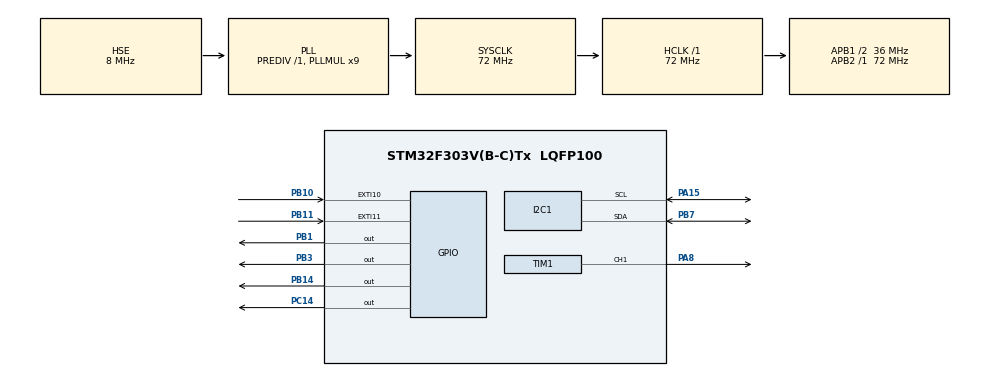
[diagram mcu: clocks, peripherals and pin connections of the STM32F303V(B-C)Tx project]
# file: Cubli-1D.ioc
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Mcu.Family=STM32F3
Mcu.Name=STM32F303V(B-C)Tx
Mcu.Package=LQFP100
NVIC.EXTI15_10_IRQn=true\:0\:0\:false\:false\:true\:true\:true
NVIC.PriorityGroup=NVIC_PRIORITYGROUP_4
NVIC.TIM2_IRQn=true\:0\:0\:false\:false\:true\:true\:true
PA13.Mode=Serial_Wire
PA13.Signal=SYS_JTMS-SWDIO
PA14.Mode=Serial_Wire
PA14.Signal=SYS_JTCK-SWCLK
PA15.GPIO_Pu=GPIO_PULLUP
PA15.Mode=I2C
PA15.Signal=I2C1_SCL
PA8.Signal=S_TIM1_CH1
PB1.Signal=GPIO_Output
PB10.GPIO_ModeDefaultEXTI=GPIO_MODE_IT_RISING
PB10.Signal=GPXTI10
PB11.GPIO_ModeDefaultEXTI=GPIO_MODE_IT_RISING
PB11.Signal=GPXTI11
PB14.Signal=GPIO_Output
PB3.Signal=GPIO_Output
PB7.GPIO_Pu=GPIO_PULLUP
PB7.Mode=I2C
PB7.Signal=I2C1_SDA
PC14-OSC32_IN.Signal=GPIO_Output
PF0-OSC_IN.Mode=HSE-External-Oscillator
PF0-OSC_IN.Signal=RCC_OSC_IN
PF1-OSC_OUT.Mode=HSE-External-Oscillator
PF1-OSC_OUT.Signal=RCC_OSC_OUT
ProjectManager.HeapSize=0x200
ProjectManager.StackSize=0x400
ProjectManager.TargetToolchain=MDK-ARM V5.32
RCC.AHBFreq_Value=72000000
RCC.APB1CLKDivider=RCC_HCLK_DIV2
RCC.APB1Freq_Value=36000000
RCC.APB1TimFreq_Value=72000000
RCC.APB2Freq_Value=72000000
RCC.APB2TimFreq_Value=72000000
RCC.CortexFreq_Value=72000000
RCC.HCLKFreq_Value=72000000
RCC.HSE_VALUE=8000000
RCC.HSI_VALUE=8000000
RCC.LSE_VALUE=32768
RCC.PLLMUL=RCC_PLL_MUL9
RCC.PLLSourceVirtual=RCC_PLLSOURCE_HSE
RCC.SYSCLKFreq_VALUE=72000000
RCC.SYSCLKSourceVirtual=RCC_SYSCLKSOURCE_PLLCLK
RCC.USBFreq_Value=72000000
SH.S_TIM1_CH1.0=TIM1_CH1,PWM Generation1 CH1
TIM1.Channel-PWM\ Generation1\ CH1=TIM_CHANNEL_1
TIM1.Period=3599
TIM2.Period=49
TIM2.Prescaler=7199
VP_TIM1_VS_ClockSourceINT.Mode=Internal
VP_TIM2_VS_ClockSourceINT.Mode=Internal
board=custom

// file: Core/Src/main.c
/* USER CODE BEGIN Header */
/**
  ******************************************************************************
  * @file           : main.c
  * @brief          : Main program body
  ******************************************************************************
  * @attention
  *
  * <h2><center>&copy; Copyright (c) 2025 STMicroelectronics.
  * All rights reserved.</center></h2>
  *
  * This software component is licensed by ST under BSD 3-Clause license,
  * the "License"; You may not use this file except in compliance with the
  * License. You may obtain a copy of the License at:
  *                        opensource.org/licenses/BSD-3-Clause
  *
  ******************************************************************************
  */
/* USER CODE END Header */
#include "main.h"
#include "i2c.h"
#include "tim.h"
#include "gpio.h"
#include "stm32f3xx_hal.h"
/* USER CODE BEGIN Includes */
#include "gyro.h"
#include "filters.h"
#include "math.h"
#include "encoder_control.h"
#include "pwm_control.h"
/* USER CODE END Includes */

/* USER CODE BEGIN PV */
extern I2C_HandleTypeDef hi2c1;
/* USER CODE END PV */

void SystemClock_Config(void);

int main(void)
{

  /* MCU Configuration--------------------------------------------------------*/

  /* Reset of all peripherals, Initializes the Flash interface and the Systick. */
  HAL_Init();

  /* Configure the system clock */
  SystemClock_Config();

  /* Initialize all configured peripherals */
  MX_GPIO_Init();
  MX_I2C1_Init();
  MX_TIM1_Init();
  MX_TIM2_Init();
  /* USER CODE BEGIN 2 */
	MPU6050_Init(&hi2c1);
	HAL_TIM_Base_Start_IT(&htim2);
	HAL_TIM_PWM_Start(&htim1, TIM_CHANNEL_1);
  /* USER CODE END 2 */

  /* Infinite loop */
  /* USER CODE BEGIN WHILE */
		HAL_GPIO_WritePin(GPIOB, GPIO_PIN_14, GPIO_PIN_SET);  // Direction LOW
	HAL_GPIO_WritePin(GPIOB, GPIO_PIN_1, GPIO_PIN_RESET);  // Start/Stop LOW (Motor OFF)
	__HAL_TIM_SET_COMPARE(&htim1, TIM_CHANNEL_1, 255);  // PWM = 255 (Motor Off)
  while (1)
  {
    /* USER CODE END WHILE */

  }
}

void SystemClock_Config(void)
{
  RCC_OscInitTypeDef RCC_OscInitStruct = {0};
  RCC_ClkInitTypeDef RCC_ClkInitStruct = {0};
  RCC_PeriphCLKInitTypeDef PeriphClkInit = {0};

  /** Initializes the RCC Oscillators according to the specified parameters
  * in the RCC_OscInitTypeDef structure.
  */
  RCC_OscInitStruct.OscillatorType = RCC_OSCILLATORTYPE_HSI|RCC_OSCILLATORTYPE_HSE;
  RCC_OscInitStruct.HSEState = RCC_HSE_ON;
  RCC_OscInitStruct.HSEPredivValue = RCC_HSE_PREDIV_DIV1;
  RCC_OscInitStruct.HSIState = RCC_HSI_ON;
  RCC_OscInitStruct.HSICalibrationValue = RCC_HSICALIBRATION_DEFAULT;
  RCC_OscInitStruct.PLL.PLLState = RCC_PLL_ON;
  RCC_OscInitStruct.PLL.PLLSource = RCC_PLLSOURCE_HSE;
  RCC_OscInitStruct.PLL.PLLMUL = RCC_PLL_MUL9;
  if (HAL_RCC_OscConfig(&RCC_OscInitStruct) != HAL_OK)
  {
    Error_Handler();
  }
  /** Initializes the CPU, AHB and APB buses clocks
  */
  RCC_ClkInitStruct.ClockType = RCC_CLOCKTYPE_HCLK|RCC_CLOCKTYPE_SYSCLK
                              |RCC_CLOCKTYPE_PCLK1|RCC_CLOCKTYPE_PCLK2;
  RCC_ClkInitStruct.SYSCLKSource = RCC_SYSCLKSOURCE_PLLCLK;
  RCC_ClkInitStruct.AHBCLKDivider = RCC_SYSCLK_DIV1;
  RCC_ClkInitStruct.APB1CLKDivider = RCC_HCLK_DIV2;
  RCC_ClkInitStruct.APB2CLKDivider = RCC_HCLK_DIV1;

  if (HAL_RCC_ClockConfig(&RCC_ClkInitStruct, FLASH_LATENCY_2) != HAL_OK)
  {
    Error_Handler();
  }
  PeriphClkInit.PeriphClockSelection = RCC_PERIPHCLK_I2C1|RCC_PERIPHCLK_TIM1;
  PeriphClkInit.I2c1ClockSelection = RCC_I2C1CLKSOURCE_HSI;
  PeriphClkInit.Tim1ClockSelection = RCC_TIM1CLK_HCLK;
  if (HAL_RCCEx_PeriphCLKConfig(&PeriphClkInit) != HAL_OK)
  {
    Error_Handler();
  }
}

void Error_Handler(void)
{
  __disable_irq();
  while (1)
  {
  }
}

/************************ (C) COPYRIGHT STMicroelectronics *****END OF FILE****/
